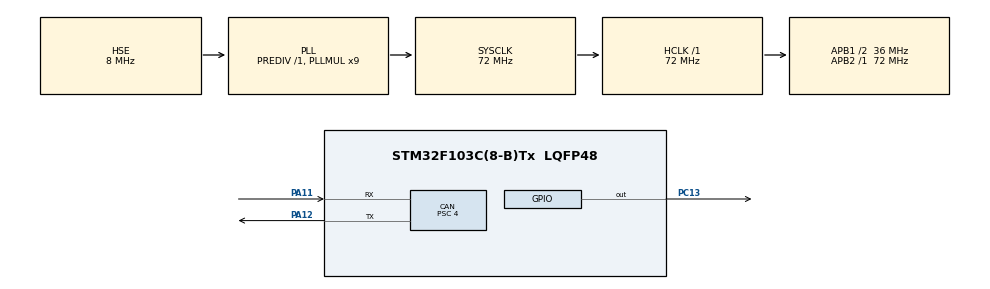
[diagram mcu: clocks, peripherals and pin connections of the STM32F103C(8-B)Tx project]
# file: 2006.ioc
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CAN.ABOM=ENABLE
CAN.AWUM=ENABLE
CAN.BS1=CAN_BS1_6TQ
CAN.BS2=CAN_BS2_2TQ
CAN.CalculateBaudRate=1000000
CAN.CalculateTimeBit=1000
CAN.CalculateTimeQuantum=111.11111111111111
CAN.Prescaler=4
Mcu.Family=STM32F1
Mcu.Name=STM32F103C(8-B)Tx
Mcu.Package=LQFP48
NVIC.CAN1_RX1_IRQn=true\:0\:0\:false\:false\:true\:true\:true\:true
NVIC.PriorityGroup=NVIC_PRIORITYGROUP_4
PA11.Mode=CAN_Activate
PA11.Signal=CAN_RX
PA12.Mode=CAN_Activate
PA12.Signal=CAN_TX
PA13.Mode=Serial_Wire
PA13.Signal=SYS_JTMS-SWDIO
PA14.Mode=Serial_Wire
PA14.Signal=SYS_JTCK-SWCLK
PC13-TAMPER-RTC.Signal=GPIO_Output
PD0-OSC_IN.Mode=HSE-External-Oscillator
PD0-OSC_IN.Signal=RCC_OSC_IN
PD1-OSC_OUT.Mode=HSE-External-Oscillator
PD1-OSC_OUT.Signal=RCC_OSC_OUT
ProjectManager.HeapSize=0x200
ProjectManager.StackSize=0x400
ProjectManager.TargetToolchain=CMake
RCC.AHBFreq_Value=72000000
RCC.APB1CLKDivider=RCC_HCLK_DIV2
RCC.APB1Freq_Value=36000000
RCC.APB1TimFreq_Value=72000000
RCC.APB2Freq_Value=72000000
RCC.APB2TimFreq_Value=72000000
RCC.HCLKFreq_Value=72000000
RCC.PLLMUL=RCC_PLL_MUL9
RCC.PLLSourceVirtual=RCC_PLLSOURCE_HSE
RCC.SYSCLKFreq_VALUE=72000000
RCC.SYSCLKSource=RCC_SYSCLKSOURCE_PLLCLK
RCC.USBFreq_Value=72000000
board=custom

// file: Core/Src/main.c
/* USER CODE BEGIN Header */
/**
  ******************************************************************************
  * @file           : main.c
  * @brief          : Main program body
  ******************************************************************************
  * @attention
  *
  * Copyright (c) 2026 STMicroelectronics.
  * All rights reserved.
  *
  * This software is licensed under terms that can be found in the LICENSE file
  * in the root directory of this software component.
  * If no LICENSE file comes with this software, it is provided AS-IS.
  *
  ******************************************************************************
  */
/* USER CODE END Header */
#include "main.h"
#include "can.h"
#include "gpio.h"

/* USER CODE BEGIN Includes */
#include "c610.h"
/* USER CODE END Includes */

/* USER CODE BEGIN PD */
#define CAN_RX_TIMEOUT_MS  500
/* USER CODE END PD */

/* USER CODE BEGIN PV */
static uint32_t last_rx_tick = 0;
/* USER CODE END PV */

void SystemClock_Config(void);

int main(void)
{

  /* MCU Configuration--------------------------------------------------------*/

  /* Reset of all peripherals, Initializes the Flash interface and the Systick. */
  HAL_Init();

  /* Configure the system clock */
  SystemClock_Config();

  /* Initialize all configured peripherals */
  MX_GPIO_Init();
  MX_CAN_Init();
  /* USER CODE BEGIN 2 */

  /* Initialize C610 ESC (CAN filter + start) */
  if (C610_Init(&hcan) != HAL_OK)
  {
    Error_Handler();
  }

  /* LED off initially (PC13 HIGH = off for active-low) */
  HAL_GPIO_WritePin(GPIOC, GPIO_PIN_13, GPIO_PIN_SET);

  /* Init receive timestamp */
  last_rx_tick = HAL_GetTick();

  /* USER CODE END 2 */

  /* Infinite loop */
  while (1)
  {

    /* USER CODE BEGIN 3 */

    /* Send 2A (= 2000mA) current to motor 4 (CAN ID 0x1FF) */
    C610_SendSingleMotor(&hcan, 3, 2000);

    /* Turn off LED if no CAN message within timeout window */
    if (HAL_GetTick() - last_rx_tick > CAN_RX_TIMEOUT_MS)
    {
      HAL_GPIO_WritePin(GPIOC, GPIO_PIN_13, GPIO_PIN_SET);
    }

    /* 1ms control period — C610 expects 1kHz refresh */
    HAL_Delay(1);

  }
  /* USER CODE END 3 */
}

void SystemClock_Config(void)
{
  RCC_OscInitTypeDef RCC_OscInitStruct = {0};
  RCC_ClkInitTypeDef RCC_ClkInitStruct = {0};

  /** Initializes the RCC Oscillators according to the specified parameters
  * in the RCC_OscInitTypeDef structure.
  */
  RCC_OscInitStruct.OscillatorType = RCC_OSCILLATORTYPE_HSE;
  RCC_OscInitStruct.HSEState = RCC_HSE_ON;
  RCC_OscInitStruct.HSEPredivValue = RCC_HSE_PREDIV_DIV1;
  RCC_OscInitStruct.HSIState = RCC_HSI_ON;
  RCC_OscInitStruct.PLL.PLLState = RCC_PLL_ON;
  RCC_OscInitStruct.PLL.PLLSource = RCC_PLLSOURCE_HSE;
  RCC_OscInitStruct.PLL.PLLMUL = RCC_PLL_MUL9;
  if (HAL_RCC_OscConfig(&RCC_OscInitStruct) != HAL_OK)
  {
    Error_Handler();
  }

  /** Initializes the CPU, AHB and APB buses clocks
  */
  RCC_ClkInitStruct.ClockType = RCC_CLOCKTYPE_HCLK|RCC_CLOCKTYPE_SYSCLK
                              |RCC_CLOCKTYPE_PCLK1|RCC_CLOCKTYPE_PCLK2;
  RCC_ClkInitStruct.SYSCLKSource = RCC_SYSCLKSOURCE_PLLCLK;
  RCC_ClkInitStruct.AHBCLKDivider = RCC_SYSCLK_DIV1;
  RCC_ClkInitStruct.APB1CLKDivider = RCC_HCLK_DIV2;
  RCC_ClkInitStruct.APB2CLKDivider = RCC_HCLK_DIV1;

  if (HAL_RCC_ClockConfig(&RCC_ClkInitStruct, FLASH_LATENCY_2) != HAL_OK)
  {
    Error_Handler();
  }
}

/* USER CODE BEGIN 4 */
/**
 * @brief  CAN FIFO0 接收中断回调 — HAL 在中断服务函数中自动调用
 * @note   调用链:
 *         CAN 硬件收到报文存入 FIFO0
 *         → 触发 CAN1_RX0_IRQn 中断
 *         → HAL_CAN_IRQHandler() 在 stm32f1xx_it.c 中被调用
 *         → HAL 读取报文并调用本回调
 *
 *         本函数在中断上下文中执行，应尽快返回，不做耗时操作。
 *         这里只做两件事: 点亮 LED 指示通信正常 + 刷新时间戳。
 *         如果需要解析反馈数据, 建议在主循环中处理或调用 C610_ParseFeedback()。
 * @param  hcan: CAN 外设句柄指针
 */
void HAL_CAN_RxFifo0MsgPendingCallback(CAN_HandleTypeDef *hcan)
{
  CAN_RxHeaderTypeDef rxHeader;   /* CAN 接收帧头信息 */
  uint8_t rxData[8];              /* 8 字节接收缓冲区 */

  /* 从 FIFO0 读取收到的报文 (非阻塞, FIFO 非空才会进来) */
  if (HAL_CAN_GetRxMessage(hcan, CAN_RX_FIFO0, &rxHeader, rxData) == HAL_OK)
  {
    /* 收到电调反馈 → PC13 拉低点亮 LED (active-low) → 刷新时间戳 */
    HAL_GPIO_TogglePin(GPIOC, GPIO_PIN_13);

    HAL_Delay(200);

    last_rx_tick = HAL_GetTick();

    /* 可选: 解析反馈数据
     * C610_Feedback_t fb;
     * C610_ParseFeedback(rxData, &fb);
     * // fb.angle / fb.speed / fb.current / fb.temp
     */
  }
}
/* USER CODE END 4 */

void Error_Handler(void)
{
  __disable_irq();
  while (1)
  {
  }
}
